# ESP32 register map
Vendor: ESPRESSIF SYSTEMS (SHANGHAI) CO., LTD.; Series: ESP32 Series; File version: 17
CPU: Xtensa LX6 r0p0, little endian, no MPU, FPU, 0 interrupt priority bits
Address unit: 32 bits
Registers are 32-bit, read-write, reset 0x0 unless marked. A register's access mark holds for its fields unless they carry their own. Offsets are from the block's base; [hi:lo] are bit positions; {n}, {i} and the like mark numbered series.

## RMT — Remote Control
Base 0x3FF56000
{0x0+4i} CH{i}DATA access not given (i=0..7)
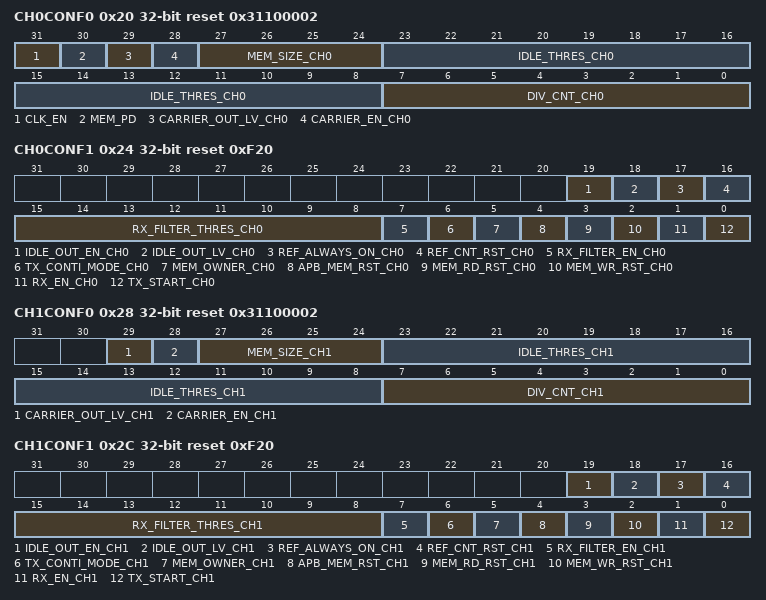
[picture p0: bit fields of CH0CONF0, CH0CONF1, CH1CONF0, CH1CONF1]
0x20 CH0CONF0 reset 0x31100002
  [31] CLK_EN — This bit is used to control clock.when software config RMT internal registers it controls the register clock.
  [30] MEM_PD — This bit is used to reduce power consumed by mem. 1:mem is in low power state.
  [29] CARRIER_OUT_LV_CH0 — This bit is used to configure the way carrier wave is modulated for channel0.1'b1:transmit on low output level 1'b0:transmit on high output level.
  [28] CARRIER_EN_CH0 — This is the carrier modulation enable control bit for channel0.
  [27:24] MEM_SIZE_CH0 — This register is used to configure the the amount of memory blocks allocated to channel0.
  [23:8] IDLE_THRES_CH0 — In receive mode when no edge is detected on the input signal for longer than reg_idle_thres_ch0 then the receive process is done.
  [7:0] DIV_CNT_CH0 — This register is used to configure the frequency divider's factor in channel0.
0x24 CH0CONF1 reset 0xF20
  [19] IDLE_OUT_EN_CH0 — This is the output enable control bit for channel0 in IDLE state.
  [18] IDLE_OUT_LV_CH0 — This bit configures the output signal's level for channel0 in IDLE state.
  [17] REF_ALWAYS_ON_CH0 — This bit is used to select base clock. 1'b1:clk_apb 1'b0:clk_ref
  [16] REF_CNT_RST_CH0 — This bit is used to reset divider in channel0.
  [15:8] RX_FILTER_THRES_CH0 — in receive mode channel0 ignore input pulse when the pulse width is smaller then this value.
  [7] RX_FILTER_EN_CH0 — This is the receive filter enable bit for channel0.
  [6] TX_CONTI_MODE_CH0 — Set this bit to continue sending from the first data to the last data in channel0 again and again.
  [5] MEM_OWNER_CH0 — This is the mark of channel0's ram usage right.1'b1：receiver uses the ram 0：transmitter uses the ram
  [4] APB_MEM_RST_CH0 — Set this bit to reset W/R ram address for channel0 by apb fifo access
  [3] MEM_RD_RST_CH0 — Set this bit to reset read ram address for channel0 by transmitter access.
  [2] MEM_WR_RST_CH0 — Set this bit to reset write ram address for channel0 by receiver access.
  [1] RX_EN_CH0 — Set this bit to enbale receving data for channel0.
  [0] TX_START_CH0 — Set this bit to start sending data for channel0.
0x28 CH1CONF0 reset 0x31100002
  [29] CARRIER_OUT_LV_CH1 — This bit is used to configure the way carrier wave is modulated for channel1.1'b1:transmit on low output level 1'b0:transmit on high output level.
  [28] CARRIER_EN_CH1 — This is the carrier modulation enable control bit for channel1.
  [27:24] MEM_SIZE_CH1 — This register is used to configure the the amount of memory blocks allocated to channel1.
  [23:8] IDLE_THRES_CH1 — This register is used to configure the the amount of memory blocks allocated to channel1.
  [7:0] DIV_CNT_CH1 — This register is used to configure the frequency divider's factor in channel1.
0x2C CH1CONF1 reset 0xF20
  [19] IDLE_OUT_EN_CH1 — This is the output enable control bit for channel1 in IDLE state.
  [18] IDLE_OUT_LV_CH1 — This bit configures the output signal's level for channel1 in IDLE state.
  [17] REF_ALWAYS_ON_CH1 — This bit is used to select base clock. 1'b1:clk_apb 1'b0:clk_ref
  [16] REF_CNT_RST_CH1 — This bit is used to reset divider in channel1.
  [15:8] RX_FILTER_THRES_CH1 — in receive mode channel1 ignore input pulse when the pulse width is smaller then this value.
  [7] RX_FILTER_EN_CH1 — This is the receive filter enable bit for channel1.
  [6] TX_CONTI_MODE_CH1 — Set this bit to continue sending from the first data to the last data in channel1 again and again.
  [5] MEM_OWNER_CH1 — This is the mark of channel1's ram usage right.1'b1：receiver uses the ram 0：transmitter uses the ram
  [4] APB_MEM_RST_CH1 — Set this bit to reset W/R ram address for channel1 by apb fifo access
  [3] MEM_RD_RST_CH1 — Set this bit to reset read ram address for channel1 by transmitter access.
  [2] MEM_WR_RST_CH1 — Set this bit to reset write ram address for channel1 by receiver access.
  [1] RX_EN_CH1 — Set this bit to enbale receving data for channel1.
  [0] TX_START_CH1 — Set this bit to start sending data for channel1.
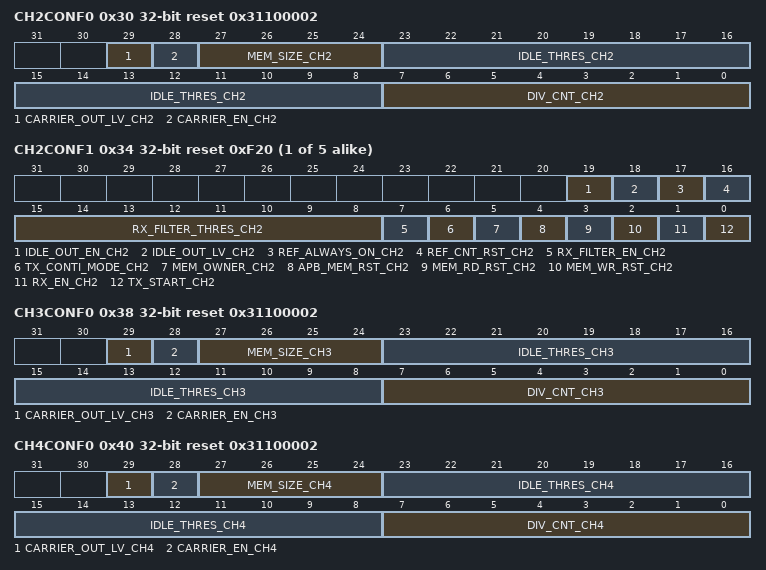
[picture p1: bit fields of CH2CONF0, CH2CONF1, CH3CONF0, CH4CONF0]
0x30 CH2CONF0 reset 0x31100002
  [29] CARRIER_OUT_LV_CH2 — This bit is used to configure carrier wave's position for channel2.1'b1:add on low level 1'b0:add on high level.
  [28] CARRIER_EN_CH2 — This is the carrier modulation enable control bit for channel2.
  [27:24] MEM_SIZE_CH2 — This register is used to configure the the amount of memory blocks allocated to channel2.
  [23:8] IDLE_THRES_CH2 — In receive mode when the counter's value is bigger than reg_idle_thres_ch2 then the receive process is done.
  [7:0] DIV_CNT_CH2 — This register is used to configure the frequency divider's factor in channel2.
{0x24+8i} CH{i}CONF1 reset 0xF20 (i=2..6)
  [19] IDLE_OUT_EN_CH{i} — This is the output enable control bit for channel{i} in IDLE state.
  [18] IDLE_OUT_LV_CH{i} — This bit configures the output signal's level for channel{i} in IDLE state.
  [17] REF_ALWAYS_ON_CH{i} — This bit is used to select base clock. 1'b1:clk_apb 1'b0:clk_ref
  [16] REF_CNT_RST_CH{i} — This bit is used to reset divider in channel{i}.
  [15:8] RX_FILTER_THRES_CH{i} — in receive mode channel{i} ignore input pulse when the pulse width is smaller then this value.
  [7] RX_FILTER_EN_CH{i} — This is the receive filter enable bit for channel{i}.
  [6] TX_CONTI_MODE_CH{i} — Set this bit to continue sending from the first data to the last data in channel{i}.
  [5] MEM_OWNER_CH{i} — This is the mark of channel{i}'s ram usage right.1'b1：receiver uses the ram 0：transmitter uses the ram
  [4] APB_MEM_RST_CH{i} — Set this bit to reset W/R ram address for channel{i} by apb fifo access
  [3] MEM_RD_RST_CH{i} — Set this bit to reset read ram address for channel{i} by transmitter access.
  [2] MEM_WR_RST_CH{i} — Set this bit to reset write ram address for channel{i} by receiver access.
  [1] RX_EN_CH{i} — Set this bit to enbale receving data for channel{i}.
  [0] TX_START_CH{i} — Set this bit to start sending data for channel{i}.
0x38 CH3CONF0 reset 0x31100002
  [29] CARRIER_OUT_LV_CH3 — This bit is used to configure carrier wave's position for channel3.1'b1:add on low level 1'b0:add on high level.
  [28] CARRIER_EN_CH3 — This is the carrier modulation enable control bit for channel3.
  [27:24] MEM_SIZE_CH3 — This register is used to configure the the amount of memory blocks allocated to channel3.
  [23:8] IDLE_THRES_CH3 — In receive mode when the counter's value is bigger than reg_idle_thres_ch3 then the receive process is done.
  [7:0] DIV_CNT_CH3 — This register is used to configure the frequency divider's factor in channel3.
0x40 CH4CONF0 reset 0x31100002
  [29] CARRIER_OUT_LV_CH4 — This bit is used to configure carrier wave's position for channel4.1'b1:add on low level 1'b0:add on high level.
  [28] CARRIER_EN_CH4 — This is the carrier modulation enable control bit for channel4.
  [27:24] MEM_SIZE_CH4 — This register is used to configure the the amount of memory blocks allocated to channel4.
  [23:8] IDLE_THRES_CH4 — In receive mode when the counter's value is bigger than reg_idle_thres_ch4 then the receive process is done.
  [7:0] DIV_CNT_CH4 — This register is used to configure the frequency divider's factor in channel4.
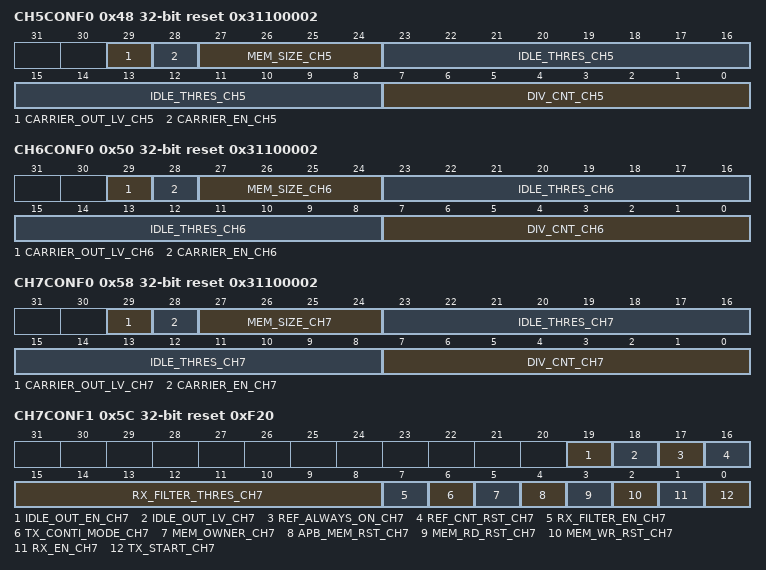
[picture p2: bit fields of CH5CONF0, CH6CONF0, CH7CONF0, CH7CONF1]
0x48 CH5CONF0 reset 0x31100002
  [29] CARRIER_OUT_LV_CH5 — This bit is used to configure carrier wave's position for channel5.1'b1:add on low level 1'b0:add on high level.
  [28] CARRIER_EN_CH5 — This is the carrier modulation enable control bit for channel5.
  [27:24] MEM_SIZE_CH5 — This register is used to configure the the amount of memory blocks allocated to channel5.
  [23:8] IDLE_THRES_CH5 — In receive mode when the counter's value is bigger than reg_idle_thres_ch5 then the receive process is done.
  [7:0] DIV_CNT_CH5 — This register is used to configure the frequency divider's factor in channel5.
0x50 CH6CONF0 reset 0x31100002
  [29] CARRIER_OUT_LV_CH6 — This bit is used to configure carrier wave's position for channel6.1'b1:add on low level 1'b0:add on high level.
  [28] CARRIER_EN_CH6 — This is the carrier modulation enable control bit for channel6.
  [27:24] MEM_SIZE_CH6 — This register is used to configure the the amount of memory blocks allocated to channel6.
  [23:8] IDLE_THRES_CH6 — In receive mode when the counter's value is bigger than reg_idle_thres_ch6 then the receive process is done.
  [7:0] DIV_CNT_CH6 — This register is used to configure the frequency divider's factor in channel6.
0x58 CH7CONF0 reset 0x31100002
  [29] CARRIER_OUT_LV_CH7 — This bit is used to configure carrier wave's position for channel7.1'b1:add on low level 1'b0:add on high level.
  [28] CARRIER_EN_CH7 — This is the carrier modulation enable control bit for channel7.
  [27:24] MEM_SIZE_CH7 — This register is used to configure the the amount of memory blocks allocated to channel7.
  [23:8] IDLE_THRES_CH7 — In receive mode when the counter's value is bigger than reg_idle_thres_ch7 then the receive process is done.
  [7:0] DIV_CNT_CH7 — This register is used to configure the frequency divider's factor in channel7.
0x5C CH7CONF1 reset 0xF20
  [19] IDLE_OUT_EN_CH7 — This is the output enable control bit for channel6 in IDLE state.
  [18] IDLE_OUT_LV_CH7 — This bit configures the output signal's level for channel7 in IDLE state.
  [17] REF_ALWAYS_ON_CH7 — This bit is used to select base clock. 1'b1:clk_apb 1'b0:clk_ref
  [16] REF_CNT_RST_CH7 — This bit is used to reset divider in channel7.
  [15:8] RX_FILTER_THRES_CH7 — in receive mode channel7 ignore input pulse when the pulse width is smaller then this value.
  [7] RX_FILTER_EN_CH7 — This is the receive filter enable bit for channel7.
  [6] TX_CONTI_MODE_CH7 — Set this bit to continue sending from the first data to the last data in channel7.
  [5] MEM_OWNER_CH7 — This is the mark of channel7's ram usage right.1'b1：receiver uses the ram 0：transmitter uses the ram
  [4] APB_MEM_RST_CH7 — Set this bit to reset W/R ram address for channel7 by apb fifo access
  [3] MEM_RD_RST_CH7 — Set this bit to reset read ram address for channel7 by transmitter access.
  [2] MEM_WR_RST_CH7 — Set this bit to reset write ram address for channel7 by receiver access.
  [1] RX_EN_CH7 — Set this bit to enbale receving data for channel7.
  [0] TX_START_CH7 — Set this bit to start sending data for channel7.
{0x60+4i} CH{i}STATUS ro (i=0..7)
  [31] APB_MEM_RD_ERR_CH{i} — The apb read memory status bit for channel{i} turns to high level when the apb read address exceeds the configuration range.
  [30] APB_MEM_WR_ERR_CH{i} — The apb write memory status bit for channel{i} turns to high level when the apb write address exceeds the configuration range.
  [29] MEM_EMPTY_CH{i} — The memory empty status bit for channel{i}. in acyclic mode, this bit turns to high level when mem_raddr_ex is greater than or equal to the configured range.
  [28] MEM_FULL_CH{i} — The memory full status bit for channel{i} turns to high level when mem_waddr_ex is greater than or equal to the configuration range.
  [27] MEM_OWNER_ERR_CH{i} — When channel{i} is configured for receive mode, this bit will turn to high level if rmt_mem_owner register is not set to 1.
  [26:24] STATE_CH{i} — The channel{i} state machine status register.3'h0 : idle, 3'h1 : send, 3'h2 : read memory, 3'h3 : receive, 3'h4 : wait.
  [21:12] MEM_RADDR_EX_CH{i} — The current memory write address of channel{i}.
  [31:0] STATUS_CH{i} — The status for channel{i}
  [9:0] MEM_WADDR_EX_CH{i} — The current memory read address of channel{i}.
{0x80+4i} CH{i}ADDR ro (i=0..7)
  [31:0] APB_MEM_ADDR_CH{i} — The ram relative address in channel{i} by apb fifo access
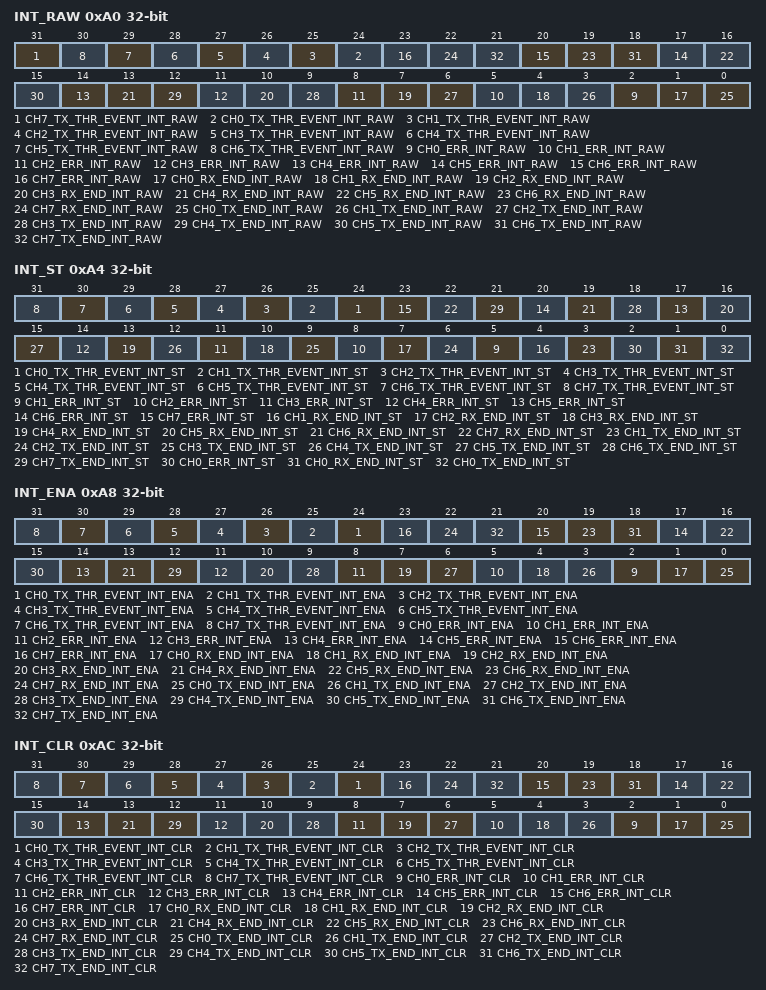
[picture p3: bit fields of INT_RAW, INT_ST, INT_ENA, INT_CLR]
0xA0 INT_RAW ro
  [31] CH7_TX_THR_EVENT_INT_RAW — The interrupt raw bit for channel7 turns to high level when transmitter in channle 7 have send datas more than reg_rmt_tx_lim_ch7 after detecting this interrupt software can updata the old datas with new datas.
  [n+24] CH{n}_TX_THR_EVENT_INT_RAW (n=0..6) — The interrupt raw bit for channel {n} turns to high level when transmitter in channle{n} have send datas more than reg_rmt_tx_lim_ch{n} after detecting this interrupt software can updata the old datas with new datas.
  [3n+2] CH{n}_ERR_INT_RAW (n=0..7) — The interrupt raw bit for channel {n} turns to high level when channle {n} detects some errors.
  [3n+1] CH{n}_RX_END_INT_RAW (n=0..7) — The interrupt raw bit for channel {n} turns to high level when the receive process is done.
  [3n] CH{n}_TX_END_INT_RAW (n=0..7) — The interrupt raw bit for channel {n} turns to high level when the transmit process is done.
0xA4 INT_ST ro
  [n+24] CH{n}_TX_THR_EVENT_INT_ST (n=0..7) — The interrupt state bit for channel {n}'s rmt_ch{n}_tx_thr_event_int_raw when mt_ch{n}_tx_thr_event_int_ena is set to 1.
  [3n+2] CH{n}_ERR_INT_ST (n=1..7) — The interrupt state bit for channel {n}'s rmt_ch{n}_err_int_raw when rmt_ch{n}_err_int_ena is set to 1.
  [3n+1] CH{n}_RX_END_INT_ST (n=1..7) — The interrupt state bit for channel {n}'s rmt_ch{n}_rx_end_int_raw when rmt_ch{n}_rx_end_int_ena is set to 1.
  [3n] CH{n}_TX_END_INT_ST (n=1..7) — The interrupt state bit for channel {n}'s mt_ch{n}_tx_end_int_raw when mt_ch{n}_tx_end_int_ena is set to 1.
  [2] CH0_ERR_INT_ST — The interrupt state bit for channel 0's rmt_ch0_err_int_raw when rmt_ch0_err_int_ena is set to 0.
  [1] CH0_RX_END_INT_ST — The interrupt state bit for channel 0's rmt_ch0_rx_end_int_raw when rmt_ch0_rx_end_int_ena is set to 0.
  [0] CH0_TX_END_INT_ST — The interrupt state bit for channel 0's mt_ch0_tx_end_int_raw when mt_ch0_tx_end_int_ena is set to 0.
0xA8 INT_ENA
  [n+24] CH{n}_TX_THR_EVENT_INT_ENA (n=0..7) — Set this bit to enable rmt_ch{n}_tx_thr_event_int_st.
  [3n+2] CH{n}_ERR_INT_ENA (n=0..7) — Set this bit to enable rmt_ch{n}_err_int_st.
  [3n+1] CH{n}_RX_END_INT_ENA (n=0..7) — Set this bit to enable rmt_ch{n}_rx_end_int_st.
  [3n] CH{n}_TX_END_INT_ENA (n=0..7) — Set this bit to enable rmt_ch{n}_tx_end_int_st.
0xAC INT_CLR wo
  [n+24] CH{n}_TX_THR_EVENT_INT_CLR (n=0..7) — Set this bit to clear the rmt_ch{n}_tx_thr_event_int_raw interrupt.
  [3n+2] CH{n}_ERR_INT_CLR (n=0..7) — Set this bit to clear the rmt_ch{n}_err_int_raw.
  [3n+1] CH{n}_RX_END_INT_CLR (n=0..7) — Set this bit to clear the rmt_ch{n}_tx_end_int_raw.
  [3n] CH{n}_TX_END_INT_CLR (n=0..7) — Set this bit to clear the rmt_ch{n}_rx_end_int_raw..
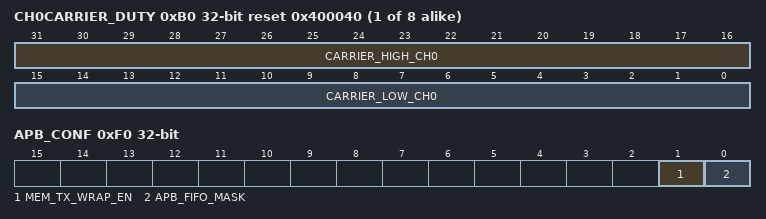
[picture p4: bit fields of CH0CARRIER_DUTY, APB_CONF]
{0xB0+4i} CH{i}CARRIER_DUTY reset 0x400040 (i=0..7)
  [31:16] CARRIER_HIGH_CH{i} — This register is used to configure carrier wave's high level value for channel{i}.
  [15:0] CARRIER_LOW_CH{i} — This register is used to configure carrier wave's low level value for channel{i}.
{0xD0+4i} CH{i}_TX_LIM reset 0x80 (i=0..7)
  [8:0] TX_LIM_CH{i} — When channel{i} sends more than reg_rmt_tx_lim_ch{i} datas then channel{i} produce the relative interrupt.
0xF0 APB_CONF
  [1] MEM_TX_WRAP_EN — when datas need to be send is more than channel's mem can store then set this bit to enable reusage of mem this bit is used together with reg_rmt_tx_lim_chn.
  [0] APB_FIFO_MASK — Set this bit to disable apb fifo access
0xFC DATE reset 0x16022600
  [31:0] DATE — This is the version register.
